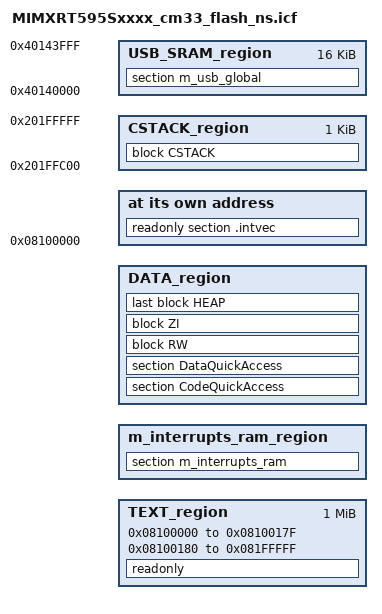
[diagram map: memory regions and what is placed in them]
/*
** ###################################################################
**     Processor:           MIMXRT595SFFOA_cm33
**     Compiler:            IAR ANSI C/C++ Compiler for ARM
**     Reference manual:    RT500 Reference Manual. Rev.0,07/2019
**     Version:             rev. 2.0, 2019-07-22
**     Build:               b190723
**
**     Abstract:
**         Linker file for the IAR ANSI C/C++ Compiler for ARM
**
**     Copyright 2016 Freescale Semiconductor, Inc.
**     Copyright 2016-2019 NXP
**     All rights reserved.
**
**     SPDX-License-Identifier: BSD-3-Clause
**
**     http:                 www.nxp.com
**     mail:                 support@nxp.com
**
** ###################################################################
*/

/* USB BDT size */
define symbol usb_bdt_size             = 0x0;
/* Stack and Heap Sizes */
if (isdefinedsymbol(__stack_size__)) {
  define symbol __size_cstack__        = __stack_size__;
} else {
  define symbol __size_cstack__        = 0x0400;
}

if (isdefinedsymbol(__heap_size__)) {
  define symbol __size_heap__          = __heap_size__;
} else {
  define symbol __size_heap__          = 0x0400;
}

/* The SRAM region [0x0-0x20000] is reserved for ROM code and app-specific use cases. */
/* The SRAM region [0x20000-0x80000] is reserved for Non-cached shared memory between M33 and DSP. */

define symbol __ram_vector_table_size__        =  isdefinedsymbol(__ram_vector_table__) ? 0x00000180 : 0;
define symbol __ram_vector_table_offset__      =  isdefinedsymbol(__ram_vector_table__) ? 0x0000017F : 0;

define symbol m_interrupts_start               = 0x08100000;
define symbol m_interrupts_end                 = 0x0810017F;

define symbol m_text_start                     = 0x08100180;
define symbol m_text_end                       = 0x081FFFFF;

define symbol m_interrupts_ram_start           = 0x20180000;
define symbol m_interrupts_ram_end             = 0x20180000 + __ram_vector_table_offset__;

define symbol m_data_start                     = m_interrupts_ram_start + __ram_vector_table_size__;
define symbol m_data_end                       = 0x201FFFFF;

define symbol m_usb_sram_start                 = 0x40140000;
define symbol m_usb_sram_end                   = 0x40143FFF;

define exported symbol __VECTOR_TABLE          = m_interrupts_start;
define exported symbol __VECTOR_RAM            = isdefinedsymbol(__ram_vector_table__) ? m_interrupts_ram_start : m_interrupts_start;
define exported symbol __RAM_VECTOR_TABLE_SIZE = __ram_vector_table_size__;

define memory mem with size = 4G;

define region TEXT_region             = mem:[from m_interrupts_start to m_interrupts_end]
                                      | mem:[from m_text_start to m_text_end];
define region m_interrupts_ram_region = mem:[from m_interrupts_ram_start to m_interrupts_ram_end];
define region DATA_region             = mem:[from m_data_start to m_data_end - __size_cstack__];
define region CSTACK_region           = mem:[from m_data_end-__size_cstack__ + 1 to m_data_end];

define block CSTACK    with alignment = 8, size = __size_cstack__   { };
define block HEAP      with alignment = 8, size = __size_heap__     { };
define block RW        { readwrite };
define block ZI        { zi };

/* regions for USB */
define region USB_BDT_region = mem:[from m_usb_sram_start to m_usb_sram_start + usb_bdt_size - 1];
define region USB_SRAM_region = mem:[from m_usb_sram_start + usb_bdt_size to m_usb_sram_end];

initialize by copy { readwrite, section .textrw , section CodeQuickAccess, section DataQuickAccess };

do not initialize  { section .noinit, section m_usb_bdt, section m_usb_global  };

place at address mem: m_interrupts_start    { readonly section .intvec };
place in TEXT_region                        { readonly };
place in m_interrupts_ram_region            { section m_interrupts_ram };
place in DATA_region                        { section CodeQuickAccess, section DataQuickAccess };
place in DATA_region                        { block RW };
place in DATA_region                        { block ZI };
place in DATA_region                        { last block HEAP };
place in CSTACK_region                      { block CSTACK };
place in USB_BDT_region                     { section m_usb_bdt };
place in USB_SRAM_region                    { section m_usb_global };
